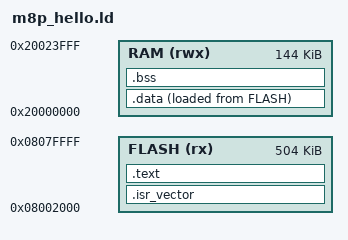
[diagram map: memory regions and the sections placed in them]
/* STM32G0B1VET6 behind the 8 KiB BTT SD card bootloader */
MEMORY
{
    FLASH (rx)  : ORIGIN = 0x08002000, LENGTH = 504K
    RAM (rwx)   : ORIGIN = 0x20000000, LENGTH = 144K
}

_estack = ORIGIN(RAM) + LENGTH(RAM);

SECTIONS
{
    .isr_vector : { KEEP(*(.isr_vector)) } > FLASH
    .text : { *(.text*) *(.rodata*) . = ALIGN(4); } > FLASH
    _sidata = LOADADDR(.data);
    .data : { _sdata = .; *(.data*) . = ALIGN(4); _edata = .; } > RAM AT > FLASH
    .bss (NOLOAD) : { _sbss = .; *(.bss*) *(COMMON) . = ALIGN(4); _ebss = .; } > RAM
}
